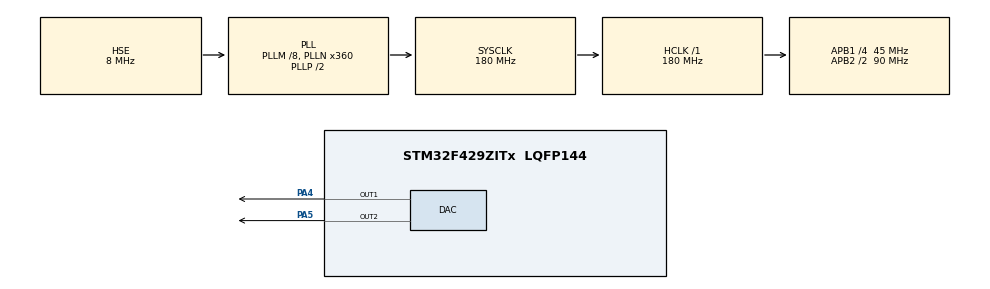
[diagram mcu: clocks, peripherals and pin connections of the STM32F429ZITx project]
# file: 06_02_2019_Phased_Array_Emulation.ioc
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Mcu.Family=STM32F4
Mcu.Name=STM32F429ZITx
Mcu.Package=LQFP144
NVIC.PriorityGroup=NVIC_PRIORITYGROUP_4
NVIC.TIM6_DAC_IRQn=true\:0\:0\:false\:false\:true\:true
PA4.Signal=COMP_DAC1_group
PA5.Signal=COMP_DAC2_group
PH0/OSC_IN.Mode=HSE-External-Oscillator
PH0/OSC_IN.Signal=RCC_OSC_IN
PH1/OSC_OUT.Mode=HSE-External-Oscillator
PH1/OSC_OUT.Signal=RCC_OSC_OUT
ProjectManager.HeapSize=0x200
ProjectManager.StackSize=0x400
ProjectManager.TargetToolchain=MDK-ARM V5
RCC.48MHZClocksFreq_Value=90000000
RCC.AHBFreq_Value=180000000
RCC.APB1CLKDivider=RCC_HCLK_DIV4
RCC.APB1Freq_Value=45000000
RCC.APB1TimFreq_Value=90000000
RCC.APB2CLKDivider=RCC_HCLK_DIV2
RCC.APB2Freq_Value=90000000
RCC.APB2TimFreq_Value=180000000
RCC.CortexFreq_Value=180000000
RCC.HCLKFreq_Value=180000000
RCC.HSE_VALUE=8000000
RCC.HSI_VALUE=16000000
RCC.LSE_VALUE=32768
RCC.PLLM=8
RCC.PLLN=360
RCC.PLLSourceVirtual=RCC_PLLSOURCE_HSE
RCC.SYSCLKFreq_VALUE=180000000
RCC.SYSCLKSource=RCC_SYSCLKSOURCE_PLLCLK
RCC.VCOOutputFreq_Value=360000000
SH.COMP_DAC1_group.0=DAC_OUT1,DAC_OUT1
SH.COMP_DAC2_group.0=DAC_OUT2,DAC_OUT2
TIM6.Period=875
TIM6.Prescaler=0
VP_TIM6_VS_ClockSourceINT.Mode=Enable_Timer
board=06_02_2019_Phased_Array_Emulation

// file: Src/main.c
/**
  ******************************************************************************
  * @file           : main.c
  * @brief          : Main program body
  ******************************************************************************
  ** This notice applies to any and all portions of this file
  * that are not between comment pairs USER CODE BEGIN and
  * USER CODE END. Other portions of this file, whether
  * inserted by the user or by software development tools
  * are owned by their respective copyright owners.
  *
  * COPYRIGHT(c) 2019 STMicroelectronics
  *
  * Redistribution and use in source and binary forms, with or without modification,
  * are permitted provided that the following conditions are met:
  *   1. Redistributions of source code must retain the above copyright notice,
  *      this list of conditions and the following disclaimer.
  *   2. Redistributions in binary form must reproduce the above copyright notice,
  *      this list of conditions and the following disclaimer in the documentation
  *      and/or other materials provided with the distribution.
  *   3. Neither the name of STMicroelectronics nor the names of its contributors
  *      may be used to endorse or promote products derived from this software
  *      without specific prior written permission.
  *
  * THIS SOFTWARE IS PROVIDED BY THE COPYRIGHT HOLDERS AND CONTRIBUTORS "AS IS"
  * AND ANY EXPRESS OR IMPLIED WARRANTIES, INCLUDING, BUT NOT LIMITED TO, THE
  * IMPLIED WARRANTIES OF MERCHANTABILITY AND FITNESS FOR A PARTICULAR PURPOSE ARE
  * DISCLAIMED. IN NO EVENT SHALL THE COPYRIGHT HOLDER OR CONTRIBUTORS BE LIABLE
  * FOR ANY DIRECT, INDIRECT, INCIDENTAL, SPECIAL, EXEMPLARY, OR CONSEQUENTIAL
  * DAMAGES (INCLUDING, BUT NOT LIMITED TO, PROCUREMENT OF SUBSTITUTE GOODS OR
  * SERVICES; LOSS OF USE, DATA, OR PROFITS; OR BUSINESS INTERRUPTION) HOWEVER
  * CAUSED AND ON ANY THEORY OF LIABILITY, WHETHER IN CONTRACT, STRICT LIABILITY,
  * OR TORT (INCLUDING NEGLIGENCE OR OTHERWISE) ARISING IN ANY WAY OUT OF THE USE
  * OF THIS SOFTWARE, EVEN IF ADVISED OF THE POSSIBILITY OF SUCH DAMAGE.
  *
  ******************************************************************************
  */
#include "main.h"
#include "stm32f4xx_hal.h"

#include "math.h"

DAC_HandleTypeDef hdac;

TIM_HandleTypeDef htim6;

/* USER CODE BEGIN PV */
/* Private variables ---------------------------------------------------------*/

#define PI 3.14159265

int diameter = 27;																								// diameter = 27mm
int velocity = 1500;																							// Velocity = 1500m/s
int frequency = 22000;																						// frequency = 22 Khz

float Wave_length;																								// Wave lentgh = ( 1000 * velocity ) / frequency mm
float Radius;																											// Radius = diameter / 2
double T1,T2,T3;																									// T(1,2,3)= (2*PI*frequency*Theta [i])/Fe		(Fe=48KHz)

float DataDAC1, DataDAC2;

#define BUFSIZE 360

uint16_t Theta [BUFSIZE];																					// Theta tab (°)
uint16_t indice,DegVALUE;																					// DegVALUE test degree value => Value codeLINE 124
uint16_t  k;

float dA [BUFSIZE];
float dB [BUFSIZE];
float dC [BUFSIZE];

float phase_H1 [BUFSIZE];
float phase_H2 [BUFSIZE];
float phase_H3 [BUFSIZE];

float signal_H1 [BUFSIZE];
float signal_H2 [BUFSIZE];
float signal_H3 [BUFSIZE];

/* USER CODE END PV */

void SystemClock_Config(void);
static void MX_GPIO_Init(void);
static void MX_DAC_Init(void);
static void MX_TIM6_Init(void);

/* USER CODE BEGIN PFP */
/* Private function prototypes -----------------------------------------------*/

/* USER CODE END PFP */

int main(void)
{
  /* USER CODE BEGIN 1 */

	Wave_length = ( 1000 * velocity ) / frequency;
	Radius = diameter / 2;
	indice = 0;
	DegVALUE = 90;

for(int j=0; j<360; j++){

	if (j == DegVALUE){
			for(int i=0; i<360; i++)
        {
           Theta [i] = i;   																										// Theta tab (°)
				}

				// THE FIRST THREE TABLES:	Distance
			for(int i=0; i<360; i++)
        {
           dA [i] = Radius * (1 - sin((Theta[i] + 30)*PI/180));   							// dA = Rayon- Rayon*sin(Theta+30)
				}

			for(int i=0; i<360; i++)
        {
           dB [i] = Radius * (1 + cos((Theta[i])*PI/180));   										// dB = Rayon + Rayon*Cos(Theta)
				}

			for(int i=0; i<360; i++)
        {
           dC [i] = Radius * (1 - sin((30 - Theta[i])*PI/180));   							// dC = Rayon - Rayon*Sin(30-Theta)
				}

				//THE SECOND THREE TABLES:	Phase
			for(int i=0; i<360; i++)
        {
           phase_H1 [i] = (dA[i] * 360) / Wave_length;
				}

			for(int i=0; i<360; i++)
        {
           phase_H2 [i] = (dB[i] * 360) / Wave_length;
				}

			for(int i=0; i<360; i++)
        {
           phase_H3 [i] = (dC[i] * 360) / Wave_length;
				}

				//THE THIRD THREE TABLES:		Signals test theta = DegVALUE°
			for(int i=0; i<360; i++)
        {
						T1 = (2*PI*frequency*Theta [i])/48000;
						signal_H1 [i] = 2048 *(sin( T1 + ((phase_H1 [j]) * PI/180)) + 1 );
				}

			for(int i=0; i<360; i++)
        {
						T2 = (2*PI*frequency*Theta [i])/48000;
						signal_H2 [i] = 2048 *(sin( T2 + ((phase_H2 [j]) * PI/180)) + 1 );
				}

			for(int i=0; i<360; i++)
        {
						T3 = (2*PI*frequency*Theta [i])/48000;
						signal_H3 [i] = 2048 *(sin( T3 + ((phase_H3 [j]) * PI/180)) + 1 );
				}
		}

}

  /* USER CODE END 1 */

  /* MCU Configuration----------------------------------------------------------*/

  /* Reset of all peripherals, Initializes the Flash interface and the Systick. */
  HAL_Init();

  /* Configure the system clock */
  SystemClock_Config();

  /* Initialize all configured peripherals */
  MX_GPIO_Init();
  MX_DAC_Init();
  MX_TIM6_Init();

  /* Infinite loop */
  /* USER CODE BEGIN WHILE */

	HAL_TIM_Base_Start_IT(&htim6);
	HAL_DAC_Start(&hdac, DAC_CHANNEL_1);
	HAL_DAC_Start(&hdac, DAC_CHANNEL_2);

  while (1)
  {

  /* USER CODE END WHILE */

  }

}

void SystemClock_Config(void)
{

  RCC_OscInitTypeDef RCC_OscInitStruct;
  RCC_ClkInitTypeDef RCC_ClkInitStruct;

    /**Configure the main internal regulator output voltage
    */
  __HAL_RCC_PWR_CLK_ENABLE();

  __HAL_PWR_VOLTAGESCALING_CONFIG(PWR_REGULATOR_VOLTAGE_SCALE1);

    /**Initializes the CPU, AHB and APB busses clocks
    */
  RCC_OscInitStruct.OscillatorType = RCC_OSCILLATORTYPE_HSE;
  RCC_OscInitStruct.HSEState = RCC_HSE_ON;
  RCC_OscInitStruct.PLL.PLLState = RCC_PLL_ON;
  RCC_OscInitStruct.PLL.PLLSource = RCC_PLLSOURCE_HSE;
  RCC_OscInitStruct.PLL.PLLM = 8;
  RCC_OscInitStruct.PLL.PLLN = 360;
  RCC_OscInitStruct.PLL.PLLP = RCC_PLLP_DIV2;
  RCC_OscInitStruct.PLL.PLLQ = 4;
  if (HAL_RCC_OscConfig(&RCC_OscInitStruct) != HAL_OK)
  {
    _Error_Handler(__FILE__, __LINE__);
  }

    /**Activate the Over-Drive mode
    */
  if (HAL_PWREx_EnableOverDrive() != HAL_OK)
  {
    _Error_Handler(__FILE__, __LINE__);
  }

    /**Initializes the CPU, AHB and APB busses clocks
    */
  RCC_ClkInitStruct.ClockType = RCC_CLOCKTYPE_HCLK|RCC_CLOCKTYPE_SYSCLK
                              |RCC_CLOCKTYPE_PCLK1|RCC_CLOCKTYPE_PCLK2;
  RCC_ClkInitStruct.SYSCLKSource = RCC_SYSCLKSOURCE_PLLCLK;
  RCC_ClkInitStruct.AHBCLKDivider = RCC_SYSCLK_DIV1;
  RCC_ClkInitStruct.APB1CLKDivider = RCC_HCLK_DIV4;
  RCC_ClkInitStruct.APB2CLKDivider = RCC_HCLK_DIV2;

  if (HAL_RCC_ClockConfig(&RCC_ClkInitStruct, FLASH_LATENCY_5) != HAL_OK)
  {
    _Error_Handler(__FILE__, __LINE__);
  }

    /**Configure the Systick interrupt time
    */
  HAL_SYSTICK_Config(HAL_RCC_GetHCLKFreq()/1000);

    /**Configure the Systick
    */
  HAL_SYSTICK_CLKSourceConfig(SYSTICK_CLKSOURCE_HCLK);

  /* SysTick_IRQn interrupt configuration */
  HAL_NVIC_SetPriority(SysTick_IRQn, 0, 0);
}

/* DAC init function */
static void MX_DAC_Init(void)
{

  DAC_ChannelConfTypeDef sConfig;

    /**DAC Initialization
    */
  hdac.Instance = DAC;
  if (HAL_DAC_Init(&hdac) != HAL_OK)
  {
    _Error_Handler(__FILE__, __LINE__);
  }

    /**DAC channel OUT1 config
    */
  sConfig.DAC_Trigger = DAC_TRIGGER_NONE;
  sConfig.DAC_OutputBuffer = DAC_OUTPUTBUFFER_ENABLE;
  if (HAL_DAC_ConfigChannel(&hdac, &sConfig, DAC_CHANNEL_1) != HAL_OK)
  {
    _Error_Handler(__FILE__, __LINE__);
  }

    /**DAC channel OUT2 config
    */
  if (HAL_DAC_ConfigChannel(&hdac, &sConfig, DAC_CHANNEL_2) != HAL_OK)
  {
    _Error_Handler(__FILE__, __LINE__);
  }

}

/* TIM6 init function */
static void MX_TIM6_Init(void)
{

  TIM_MasterConfigTypeDef sMasterConfig;

  htim6.Instance = TIM6;
  htim6.Init.Prescaler = 0;
  htim6.Init.CounterMode = TIM_COUNTERMODE_UP;
  htim6.Init.Period = 875;
  if (HAL_TIM_Base_Init(&htim6) != HAL_OK)
  {
    _Error_Handler(__FILE__, __LINE__);
  }

  sMasterConfig.MasterOutputTrigger = TIM_TRGO_RESET;
  sMasterConfig.MasterSlaveMode = TIM_MASTERSLAVEMODE_DISABLE;
  if (HAL_TIMEx_MasterConfigSynchronization(&htim6, &sMasterConfig) != HAL_OK)
  {
    _Error_Handler(__FILE__, __LINE__);
  }

}

/** Configure pins as
        * Analog
        * Input
        * Output
        * EVENT_OUT
        * EXTI
*/
static void MX_GPIO_Init(void)
{

  /* GPIO Ports Clock Enable */
  __HAL_RCC_GPIOH_CLK_ENABLE();
  __HAL_RCC_GPIOA_CLK_ENABLE();

}

void _Error_Handler(char *file, int line)
{
  while(1)
  {
  }
}

/************************ (C) COPYRIGHT STMicroelectronics *****END OF FILE****/
